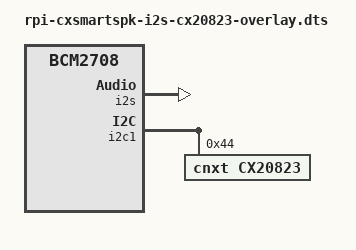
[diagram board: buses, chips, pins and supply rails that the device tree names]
// Definitions for audioinjector.net audio add on soundcard
/dts-v1/;
/plugin/;

/ {
	compatible = "brcm,bcm2708";

	fragment@0 {
		target = <&i2s>;
		__overlay__ {
			status = "okay";
		};
	};

	fragment@1 {
		target = <&i2c1>;
		__overlay__ {
			#address-cells = <1>;
			#size-cells = <0>;
			status = "okay";

			cx20823:cx20823@44{
				#sound-dai-cells = <0>;
				compatible = "cnxt,cx20823";
				reg = <0x44>;
				status = "okay";
			};

		};
	};

	fragment@2 {
		target = <&sound>;
		__overlay__ {
			compatible = "simple-audio-card";
			pinctrl-names = "default";
			simple-audio-card,name = "cx-smart-speaker";
			simple-audio-card,format = "i2s";
			simple-audio-card,routing =
			"AMic", "Mic Jack";
			simple-audio-card,widgets =
			"Microphone", "Mic Jack";
			simple-audio-card,bitclock-master =
			<&sound_master>;
			simple-audio-card,frame-master =
			<&sound_master>;
			status = "okay";
			sound_master: simple-audio-card,cpu {
				sound-dai = <&i2s>;
			};

			simple-audio-card,codec {
				sound-dai = <&cx20823>;
			};
		};
	};

};
